# TC37XPD register map
Vendor: Infineon; Series: ATVMC; File version: 100
CPU: other r0p0, little endian, MPU, FPU, vendor SysTick, 4 interrupt priority bits
Registers are 32-bit, read-write, reset 0x0 unless marked. A register's access mark holds for its fields unless they carry their own. Offsets are from the block's base; [hi:lo] are bit positions; {n}, {i} and the like mark numbered series.

## P21 — General Purpose I O Ports and Peripheral I O Lines
Base 0xF003B500
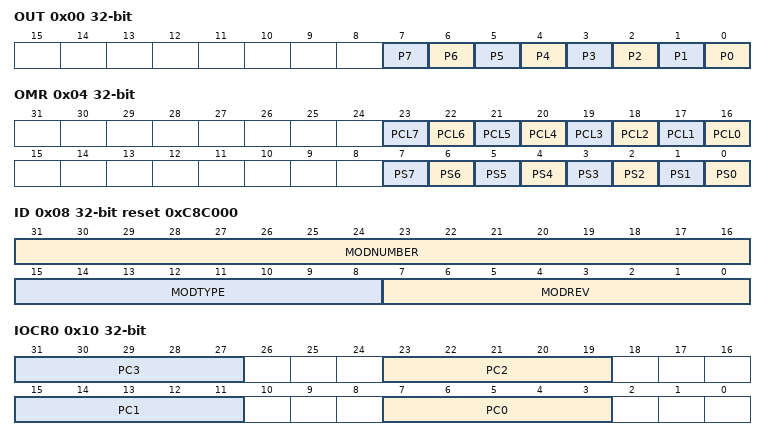
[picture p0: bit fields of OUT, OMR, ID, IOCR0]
0x00 OUT — Port 21 Output Register resetvalue={:0x0}
  [n] P{n} (n=0..7) — Output Bit 15. This bit determines the level at the output pin Pn.x if the output is selected as GPIO output. Pn.x can also be set or cleared by control bits of the Pn OMSR Pn OMCR or Pn OMR registers.
0x04 OMR wo — Port 21 Output Modification Register resetvalue={:0x0}
  [n+16] PCL{n} (n=0..7) — Clear Bit 15. Setting this bit will clear or toggle the corresponding bit in the port output register Pn OUT. Read as 0. The function of this bit is shown in Table .
  [n] PS{n} (n=0..7) — Set Bit 15. Setting this bit will set or toggle the corresponding bit in the port output register Pn OUT. Read as 0. The function of this bit is shown in Table .
0x08 ID ro reset 0xC8C000 (reset mask 0xFFFFFF00) — Port 21 Identification Register resetvalue={:0x0C8C000}
  [31:16] MODNUMBER — Module Number. This bit field defines the module identification number. The value for the Ports module is 00C8
  [15:8] MODTYPE — Module Type. This bit field is C0 H . It defines a 32 bit module
  [7:0] MODREV — Module Revision Number. This bit field indicates the revision number of the TC39x module 01 H 160 160 first revision .
0x10 IOCR0 (reset mask 0xEFEFEFEF) — Port 21 Input Output Control Register 0 resetvalue={:0x0,:0x0,:0x10101010,:0x10101010}
  [8n+7:8n+3] PC{n} (n=0..3) — Port Control for Pin 3. This bit field defines the Port n line x functionality according to Table only input selection apply.
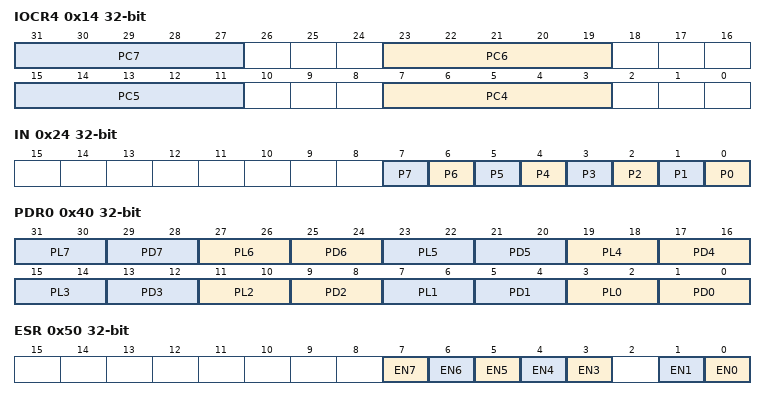
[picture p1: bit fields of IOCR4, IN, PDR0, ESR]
0x14 IOCR4 (reset mask 0xEFEFEFEF) — Port 21 Input Output Control Register 4 resetvalue={:0x0,:0x0,:0x10101010,:0x10101010}
  [8n-25:8n-29] PC{n} (n=4..7) — Port Control for Port 21 Pin 7. This bit field defines the Port n line x functionality according to Table only input selection apply.
0x24 IN ro (reset mask 0xFFFFFF00) — Port 21 Input Register resetvalue={:0x0}
  [n] P{n} (n=0..7) — Input Bit 15. This bit indicates the level at the input pin Pn.x.
0x40 PDR0 reset not defined — Port 21 Pad Driver Mode Register 0 resetvalue={:0x0,:0x0,After SSW execution:0x22222222,After SSW execution:0x22222222}
  [4n+3:4n+2] PL{n} (n=0..7) — Pad Level Selection for Pin 7
  [4n+1:4n] PD{n} (n=0..7) — Pad Driver Mode for Pin 7
0x50 ESR — Port 21 Emergency Stop Register resetvalue={:0x0}
  [n] EN{n} (n=3..7) — Emergency Stop Enable for Pin 15. This bit enables the emergency stop function for all GPIO lines. If the emergency stop condition is met and enabled the output selection is automatically switched from alternate output function to GPIO input function.
  [1] EN1 — Emergency Stop Enable for Pin 15. This bit enables the emergency stop function for all GPIO lines. If the emergency stop condition is met and enabled the output selection is automatically switched from alternate output function to GPIO input function.
  [0] EN0 — Emergency Stop Enable for Pin 15. This bit enables the emergency stop function for all GPIO lines. If the emergency stop condition is met and enabled the output selection is automatically switched from alternate output function to GPIO input function.
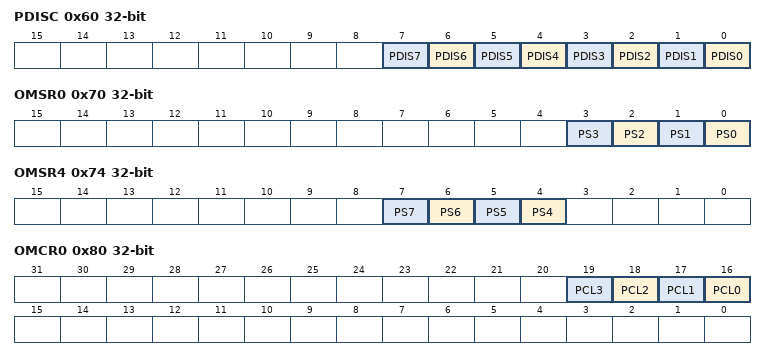
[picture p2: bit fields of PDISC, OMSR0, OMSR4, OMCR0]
0x60 PDISC (reset mask 0xFFFFFF00) — Port 21 Pin Function Decision Control Register resetvalue={:0x0,:0x0,After SSW execution:0x0,After SSW execution:0x0}
  [n] PDIS{n} (n=0..7) — Pin Function Decision Control for Pin 15. This bit selects the function of the port pad.
0x70 OMSR0 wo — Port 21 Output Modification Set Register 0 resetvalue={:0x0}
  [n] PS{n} (n=0..3) — Set Bit 3. Setting this bit will set the corresponding bit in the port output register Pn OUT. Read as 0.
0x74 OMSR4 wo — Port 21 Output Modification Set Register 4 resetvalue={:0x0}
  [n] PS{n} (n=4..7) — Set Bit 7. Setting this bit will set the corresponding bit in the port output register Pn OUT. Read as 0.
0x80 OMCR0 wo — Port 21 Output Modification Clear Register 0 resetvalue={:0x0}
  [n+16] PCL{n} (n=0..3) — Clear Bit 3. Setting this bit will clear the corresponding bit in the port output register Pn OUT. Read as 0.
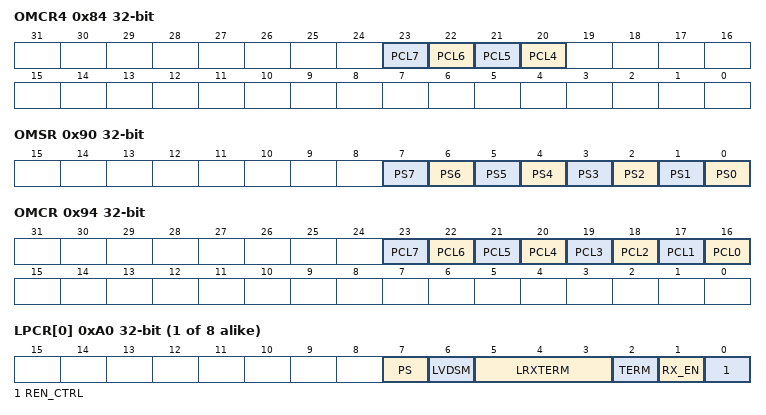
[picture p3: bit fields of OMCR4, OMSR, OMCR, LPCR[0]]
0x84 OMCR4 wo — Port 21 Output Modification Clear Register 4 resetvalue={:0x0}
  [n+16] PCL{n} (n=4..7) — Clear Bit 7. Setting this bit will clear the corresponding bit in the port output register Pn OUT. Read as 0.
0x90 OMSR wo — Port 21 Output Modification Set Register resetvalue={:0x0}
  [n] PS{n} (n=0..7) — Set Bit 15. Setting this bit will set the corresponding bit in the port output register Pn OUT. Read as 0.
0x94 OMCR wo — Port 21 Output Modification Clear Register resetvalue={:0x0}
  [n+16] PCL{n} (n=0..7) — Clear Bit 15. Setting this bit will clear the corresponding bit in the port output register Pn OUT. Read as 0.
{0xA0+4i} LPCR[{i}] (i=0..7) (reset mask 0xFFFF0000) — Port 21 LVDS Pad Control Register 0 resetvalue={:0x0C0,:0x54C0,After SSW execution:0x54E0,After SSW execution:0x0E0}
  [7] PS — Pad Supply Selection. Selects between 5V or 3.3V supply on V EXT for the pad pair. Used in RX and TX pads Driven to LVDS pad control 8220 LVDS 5EN 8221 . Needs also be connected to the related bias distributor.
  [6] LVDSM — LVDS M Mode. Selects reduced frequency mode 8220 LVDS M 8221 of the receiver. This mode reduces the static current of the RX pad. The max data rate is reduced to 160 160 Mbps 80 160 MHz . Driven to LVDS pad control 8220 LVDS MEN 8221 .
  [5:3] LRXTERM — LVDS RX Poly resistor configuration value. Programming bits for the on die poly resistor termination. The value is configured during production test. Each chip configuration on this bit field is unique and configured during production testing. Please check PHY design specification for detailed configuration values. The value is configured by Startup SW during start up phase of the chip Driven to LVDS pad control 8220 RTERM PROG 2 0 8221 The configuration value shall not be changed by user after start up for a guaranteed behavior.
  [2] TERM — Select Receiver Termination Mode. Selects a suitable internal load resistor between both pads. Driven to LVDS pad control 8220 RTERM EN 8221 .
  [1] RX_EN — Enable Receive LVDS. Enable the receive LVDS disable CMOS path. If this bit is set to 0 8211 no transfer from the LVDS sender can be received and the receiver LVDS is in low power state. Driven to LVDS pad control 8220 LVDSEN 8221 .
  [0] REN_CTRL — LVDS RX EN controller. The LVDS RX EN control function can be selected from the Port default or HSCT module where this is connected .
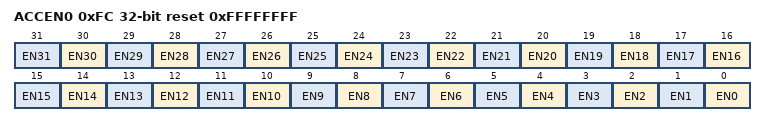
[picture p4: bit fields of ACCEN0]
0xFC ACCEN0 reset 0xFFFFFFFF — Port 21 Access Enable Register 0 resetvalue={:0x0FFFFFFFF}
  [n] EN{n} (n=0..31) — Access Enable for Master TAG ID 31. This bit enables write access to the module kernel addresses for transactions with the Master TAG ID n
